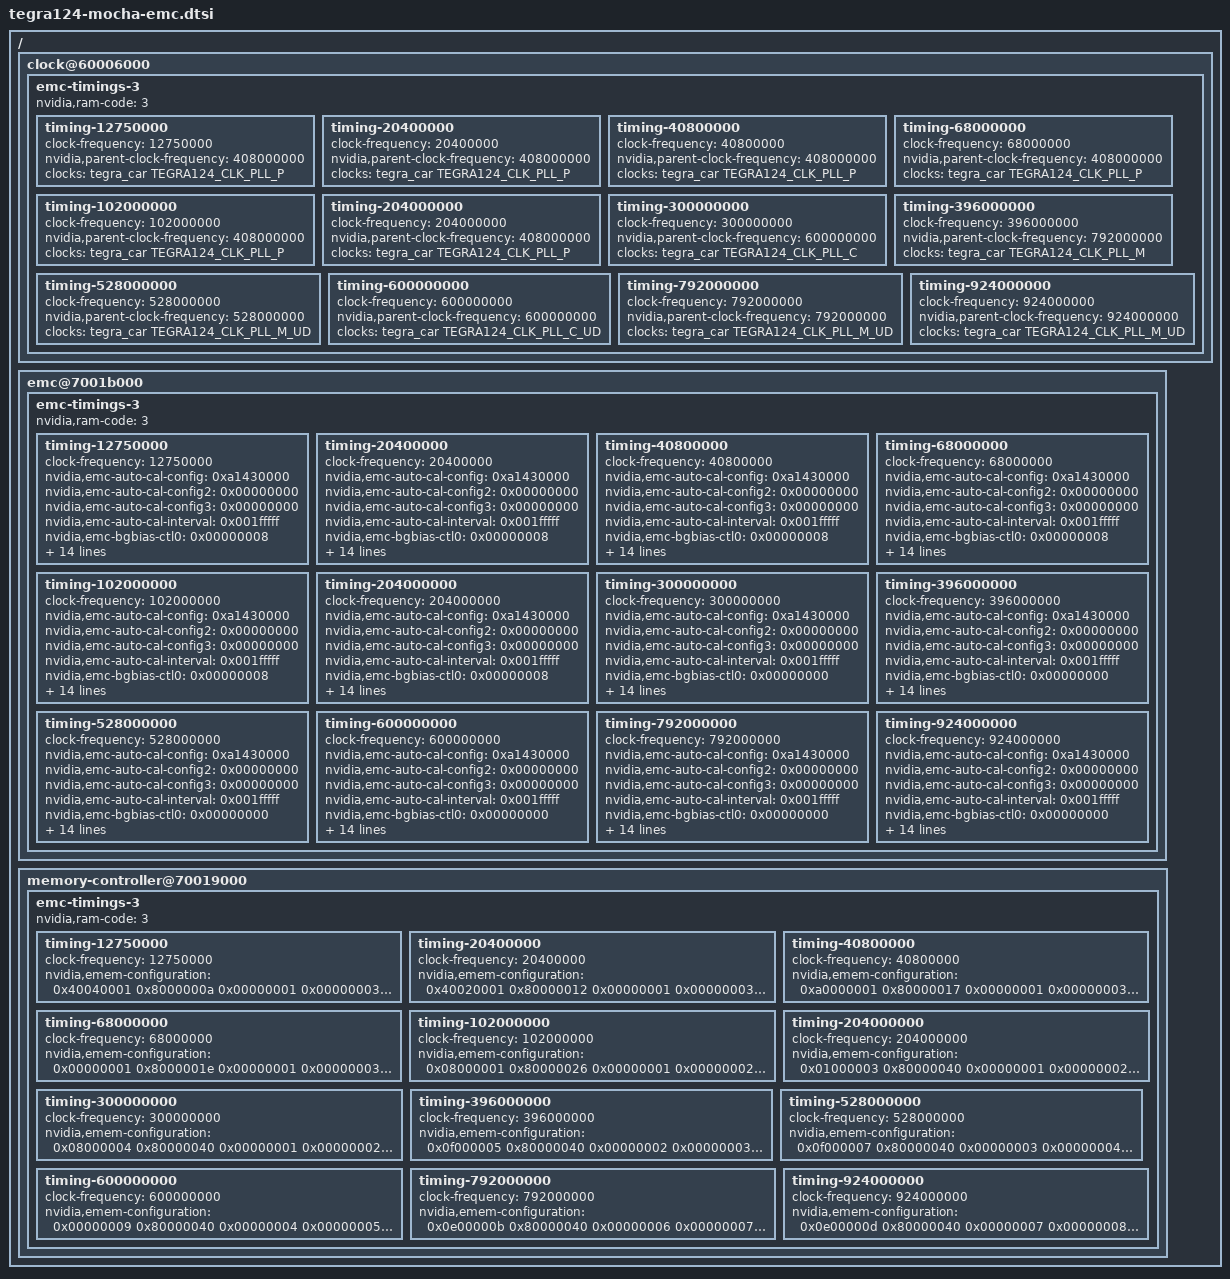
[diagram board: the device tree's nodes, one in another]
/*
 * arch/arm/boot/dts/tegra124-mocha-emc.dtsi
 *
 * Copyright (c) 2018, Dmitry Alexandrov.  All rights reserved.
 *
 * This program is free software; you can redistribute it and/or modify
 * it under the terms of the GNU General Public License as published by
 * the Free Software Foundation; either version 2 of the License, or
 * (at your option) any later version.
 *
 * This program is distributed in the hope that it will be useful, but WITHOUT
 * ANY WARRANTY; without even the implied warranty of MERCHANTABILITY or
 * FITNESS FOR A PARTICULAR PURPOSE.  See the GNU General Public License for
 * more details.
 *
 * You should have received a copy of the GNU General Public License along
 * with this program; if not, write to the Free Software Foundation, Inc.,
 * 51 Franklin Street, Fifth Floor, Boston, MA  02110-1301, USA.
 */
 
/ {
	clock@60006000 {
		emc-timings-3 {
			nvidia,ram-code = <3>;

			timing-12750000 {
				clock-frequency = <12750000>;
				nvidia,parent-clock-frequency = <408000000>;
				clocks = <&tegra_car TEGRA124_CLK_PLL_P>;
				clock-names = "emc-parent";
			};
			timing-20400000 {
				clock-frequency = <20400000>;
				nvidia,parent-clock-frequency = <408000000>;
				clocks = <&tegra_car TEGRA124_CLK_PLL_P>;
				clock-names = "emc-parent";
			};
			timing-40800000 {
				clock-frequency = <40800000>;
				nvidia,parent-clock-frequency = <408000000>;
				clocks = <&tegra_car TEGRA124_CLK_PLL_P>;
				clock-names = "emc-parent";
			};
			timing-68000000 {
				clock-frequency = <68000000>;
				nvidia,parent-clock-frequency = <408000000>;
				clocks = <&tegra_car TEGRA124_CLK_PLL_P>;
				clock-names = "emc-parent";
			};
			timing-102000000 {
				clock-frequency = <102000000>;
				nvidia,parent-clock-frequency = <408000000>;
				clocks = <&tegra_car TEGRA124_CLK_PLL_P>;
				clock-names = "emc-parent";
			};
			timing-204000000 {
				clock-frequency = <204000000>;
				nvidia,parent-clock-frequency = <408000000>;
				clocks = <&tegra_car TEGRA124_CLK_PLL_P>;
				clock-names = "emc-parent";
			};
			timing-300000000 {
				clock-frequency = <300000000>;
				nvidia,parent-clock-frequency = <600000000>;
				clocks = <&tegra_car TEGRA124_CLK_PLL_C>;
				clock-names = "emc-parent";
			};
			timing-396000000 {
				clock-frequency = <396000000>;
				nvidia,parent-clock-frequency = <792000000>;
				clocks = <&tegra_car TEGRA124_CLK_PLL_M>;
				clock-names = "emc-parent";
			};
			timing-528000000 {
				clock-frequency = <528000000>;
				nvidia,parent-clock-frequency = <528000000>;
				clocks = <&tegra_car TEGRA124_CLK_PLL_M_UD>;
				clock-names = "emc-parent";
			};
			timing-600000000 {
				clock-frequency = <600000000>;
				nvidia,parent-clock-frequency = <600000000>;
				clocks = <&tegra_car TEGRA124_CLK_PLL_C_UD>;
				clock-names = "emc-parent";
			};
			timing-792000000 {
				clock-frequency = <792000000>;
				nvidia,parent-clock-frequency = <792000000>;
				clocks = <&tegra_car TEGRA124_CLK_PLL_M_UD>;
				clock-names = "emc-parent";
			};
			timing-924000000 {
				clock-frequency = <924000000>;
				nvidia,parent-clock-frequency = <924000000>;
				clocks = <&tegra_car TEGRA124_CLK_PLL_M_UD>;
				clock-names = "emc-parent";
			};
		};
	};

	emc@7001b000 {
		emc-timings-3 {
			nvidia,ram-code = <3>;

			timing-12750000 {
				clock-frequency = <12750000>;

				nvidia,emc-auto-cal-config = <0xa1430000>;
				nvidia,emc-auto-cal-config2 = <0x00000000>;
				nvidia,emc-auto-cal-config3 = <0x00000000>;
				nvidia,emc-auto-cal-interval = <0x001fffff>;
				nvidia,emc-bgbias-ctl0 = <0x00000008>;
				nvidia,emc-cfg = <0xf3200000>;
				nvidia,emc-cfg-2 = <0x000008c7>;
				nvidia,emc-ctt-term-ctrl = <0x00000802>;
				nvidia,emc-mode-1 = <0x00010083>;
				nvidia,emc-mode-2 = <0x00020004>;
				nvidia,emc-mode-4 = <0x800b0000>;
				nvidia,emc-mode-reset = <0x00000000>;
				nvidia,emc-mrs-wait-cnt = <0x000d0011>;
				nvidia,emc-sel-dpd-ctrl = <0x0004013c>;
				nvidia,emc-xm2dqspadctrl2 = <0x0130b018>;
				nvidia,emc-zcal-cnt-long = <0x00000015>;
				nvidia,emc-zcal-interval = <0x00064000>;

				nvidia,emc-configuration = <
					0x00000000
					0x00000001
					0x00000000
					0x00000002
					0x00000006
					0x00000006
					0x00000008
					0x00000003
					0x0000000a
					0x00000002
					0x00000002
					0x00000001
					0x00000002
					0x00000000
					0x00000003
					0x00000003
					0x00000006
					0x00000002
					0x00000000
					0x00000005
					0x00000005
					0x00010000
					0x00000003
					0x00000000
					0x00000000
					0x00000000
					0x00000000
					0x00000004
					0x0000000c
					0x0000000d
					0x0000000f
					0x00000030
					0x00000000
					0x0000000c
					0x00000002
					0x00000002
					0x00000006
					0x00000000
					0x00000001
					0x0000000c
					0x00000003
					0x00000002
					0x00000003
					0x00000003
					0x00000003
					0x00000006
					0x00000007
					0x00000003
					0x00000003
					0x00000036
					0x00000000
					0x00000000
					0x00000000
					0x1363a296
					0x005800a0
					0x00008000
					0x00090000
					0x00090000
					0x00090000
					0x00090000
					0x00090000
					0x00090000
					0x00090000
					0x00090000
					0x00090000
					0x00090000
					0x00090000
					0x00090000
					0x00090000
					0x00090000
					0x00090000
					0x00090000
					0x00000000
					0x00000000
					0x00000000
					0x00000000
					0x00000000
					0x00000000
					0x00000000
					0x00000000
					0x000fc000
					0x000fc000
					0x00000000
					0x000fc000
					0x000fc000
					0x00000000
					0x00000000
					0x00000000
					0x00000000
					0x00000000
					0x00000000
					0x00000000
					0x00000000
					0x00000000
					0x00000000
					0x00000000
					0x00000000
					0x00000000
					0x00000000
					0x00000000
					0x00000000
					0x00000000
					0x00000000
					0x00000000
					0x00000000
					0x00000000
					0x00000000
					0x00000000
					0x00000000
					0x00000000
					0x000fc000
					0x000fc000
					0x000fc000
					0x000fc000
					0x0000fc00
					0x0000fc00
					0x0000fc00
					0x0000fc00
					0x00000200
					0x00000000
					0x00100100
					0x00000000
					0x00000000
					0x77ffc000
					0x00000303
					0x81f1f008
					0x07070000
					0x0000003f
					0x015ddddd
					0x51451400
					0x00514514
					0x00514514
					0x51451400
					0x0000003f
					0x00000000
					0x00000000
					0x00000011
					0x000d0011
					0x00000000
					0x00000003
					0x0000f3f3
					0x80000164
					0x0000000a
				>;
			};

			timing-20400000 {
				clock-frequency = <20400000>;

				nvidia,emc-auto-cal-config = <0xa1430000>;
				nvidia,emc-auto-cal-config2 = <0x00000000>;
				nvidia,emc-auto-cal-config3 = <0x00000000>;
				nvidia,emc-auto-cal-interval = <0x001fffff>;
				nvidia,emc-bgbias-ctl0 = <0x00000008>;
				nvidia,emc-cfg = <0xf3200000>;
				nvidia,emc-cfg-2 = <0x000008c7>;
				nvidia,emc-ctt-term-ctrl = <0x00000802>;
				nvidia,emc-mode-1 = <0x00010083>;
				nvidia,emc-mode-2 = <0x00020004>;
				nvidia,emc-mode-4 = <0x800b0000>;
				nvidia,emc-mode-reset = <0x00000000>;
				nvidia,emc-mrs-wait-cnt = <0x00150011>;
				nvidia,emc-sel-dpd-ctrl = <0x0004013c>;
				nvidia,emc-xm2dqspadctrl2 = <0x0130b018>;
				nvidia,emc-zcal-cnt-long = <0x00000015>;
				nvidia,emc-zcal-interval = <0x00064000>;

				nvidia,emc-configuration = <
					0x00000001
					0x00000002
					0x00000000
					0x00000002
					0x00000006
					0x00000006
					0x00000008
					0x00000003
					0x0000000a
					0x00000002
					0x00000002
					0x00000001
					0x00000002
					0x00000000
					0x00000003
					0x00000003
					0x00000006
					0x00000002
					0x00000000
					0x00000005
					0x00000005
					0x00010000
					0x00000003
					0x00000000
					0x00000000
					0x00000000
					0x00000000
					0x00000004
					0x0000000c
					0x0000000d
					0x0000000f
					0x0000004d
					0x00000000
					0x00000013
					0x00000002
					0x00000002
					0x00000006
					0x00000000
					0x00000001
					0x0000000c
					0x00000003
					0x00000003
					0x00000003
					0x00000003
					0x00000003
					0x00000006
					0x00000007
					0x00000003
					0x00000003
					0x00000055
					0x00000000
					0x00000000
					0x00000000
					0x1363a296
					0x005800a0
					0x00008000
					0x00090000
					0x00090000
					0x00090000
					0x00090000
					0x00090000
					0x00090000
					0x00090000
					0x00090000
					0x00090000
					0x00090000
					0x00090000
					0x00090000
					0x00090000
					0x00090000
					0x00090000
					0x00090000
					0x00000000
					0x00000000
					0x00000000
					0x00000000
					0x00000000
					0x00000000
					0x00000000
					0x00000000
					0x000fc000
					0x000fc000
					0x00000000
					0x000fc000
					0x000fc000
					0x00000000
					0x00000000
					0x00000000
					0x00000000
					0x00000000
					0x00000000
					0x00000000
					0x00000000
					0x00000000
					0x00000000
					0x00000000
					0x00000000
					0x00000000
					0x00000000
					0x00000000
					0x00000000
					0x00000000
					0x00000000
					0x00000000
					0x00000000
					0x00000000
					0x00000000
					0x00000000
					0x00000000
					0x00000000
					0x000fc000
					0x000fc000
					0x000fc000
					0x000fc000
					0x0000fc00
					0x0000fc00
					0x0000fc00
					0x0000fc00
					0x00000200
					0x00000000
					0x00100100
					0x00000000
					0x00000000
					0x77ffc000
					0x00000303
					0x81f1f008
					0x07070000
					0x0000003f
					0x015ddddd
					0x51451400
					0x00514514
					0x00514514
					0x51451400
					0x0000003f
					0x00000000
					0x00000000
					0x00000011
					0x00150011
					0x00000000
					0x00000003
					0x0000f3f3
					0x8000019f
					0x0000000a
				>;
			};

			timing-40800000 {
				clock-frequency = <40800000>;

				nvidia,emc-auto-cal-config = <0xa1430000>;
				nvidia,emc-auto-cal-config2 = <0x00000000>;
				nvidia,emc-auto-cal-config3 = <0x00000000>;
				nvidia,emc-auto-cal-interval = <0x001fffff>;
				nvidia,emc-bgbias-ctl0 = <0x00000008>;
				nvidia,emc-cfg = <0xf3200000>;
				nvidia,emc-cfg-2 = <0x000008c7>;
				nvidia,emc-ctt-term-ctrl = <0x00000802>;
				nvidia,emc-mode-1 = <0x00010083>;
				nvidia,emc-mode-2 = <0x00020004>;
				nvidia,emc-mode-4 = <0x800b0000>;
				nvidia,emc-mode-reset = <0x00000000>;
				nvidia,emc-mrs-wait-cnt = <0x00290011>;
				nvidia,emc-sel-dpd-ctrl = <0x0004013c>;
				nvidia,emc-xm2dqspadctrl2 = <0x0130b018>;
				nvidia,emc-zcal-cnt-long = <0x00000015>;
				nvidia,emc-zcal-interval = <0x00064000>;

				nvidia,emc-configuration = <
					0x00000002
					0x00000005
					0x00000000
					0x00000002
					0x00000006
					0x00000006
					0x00000008
					0x00000003
					0x0000000a
					0x00000002
					0x00000002
					0x00000001
					0x00000002
					0x00000000
					0x00000003
					0x00000003
					0x00000006
					0x00000002
					0x00000000
					0x00000005
					0x00000005
					0x00010000
					0x00000003
					0x00000000
					0x00000000
					0x00000000
					0x00000000
					0x00000004
					0x0000000c
					0x0000000d
					0x0000000f
					0x0000009a
					0x00000000
					0x00000026
					0x00000002
					0x00000002
					0x00000006
					0x00000000
					0x00000001
					0x0000000c
					0x00000006
					0x00000006
					0x00000003
					0x00000003
					0x00000003
					0x00000006
					0x00000008
					0x00000003
					0x00000003
					0x000000aa
					0x00000000
					0x00000000
					0x00000000
					0x1363a296
					0x005800a0
					0x00008000
					0x00090000
					0x00090000
					0x00090000
					0x00090000
					0x00090000
					0x00090000
					0x00090000
					0x00090000
					0x00090000
					0x00090000
					0x00090000
					0x00090000
					0x00090000
					0x00090000
					0x00090000
					0x00090000
					0x00000000
					0x00000000
					0x00000000
					0x00000000
					0x00000000
					0x00000000
					0x00000000
					0x00000000
					0x000fc000
					0x000fc000
					0x00000000
					0x000fc000
					0x000fc000
					0x00000000
					0x00000000
					0x00000000
					0x00000000
					0x00000000
					0x00000000
					0x00000000
					0x00000000
					0x00000000
					0x00000000
					0x00000000
					0x00000000
					0x00000000
					0x00000000
					0x00000000
					0x00000000
					0x00000000
					0x00000000
					0x00000000
					0x00000000
					0x00000000
					0x00000000
					0x00000000
					0x00000000
					0x00000000
					0x000fc000
					0x000fc000
					0x000fc000
					0x000fc000
					0x0000fc00
					0x0000fc00
					0x0000fc00
					0x0000fc00
					0x00000200
					0x00000000
					0x00100100
					0x00000000
					0x00000000
					0x77ffc000
					0x00000303
					0x81f1f008
					0x07070000
					0x0000003f
					0x015ddddd
					0x51451400
					0x00514514
					0x00514514
					0x51451400
					0x0000003f
					0x00000000
					0x00000000
					0x00000011
					0x00290011
					0x00000000
					0x00000003
					0x0000f3f3
					0x8000023a
					0x0000000a
				>;
			};

			timing-68000000 {
				clock-frequency = <68000000>;

				nvidia,emc-auto-cal-config = <0xa1430000>;
				nvidia,emc-auto-cal-config2 = <0x00000000>;
				nvidia,emc-auto-cal-config3 = <0x00000000>;
				nvidia,emc-auto-cal-interval = <0x001fffff>;
				nvidia,emc-bgbias-ctl0 = <0x00000008>;
				nvidia,emc-cfg = <0xf3200000>;
				nvidia,emc-cfg-2 = <0x000008c7>;
				nvidia,emc-ctt-term-ctrl = <0x00000802>;
				nvidia,emc-mode-1 = <0x00010083>;
				nvidia,emc-mode-2 = <0x00020004>;
				nvidia,emc-mode-4 = <0x800b0000>;
				nvidia,emc-mode-reset = <0x00000000>;
				nvidia,emc-mrs-wait-cnt = <0x00440011>;
				nvidia,emc-sel-dpd-ctrl = <0x0004013c>;
				nvidia,emc-xm2dqspadctrl2 = <0x0130b018>;
				nvidia,emc-zcal-cnt-long = <0x00000015>;
				nvidia,emc-zcal-interval = <0x00064000>;

				nvidia,emc-configuration = <
					0x00000004
					0x00000008
					0x00000000
					0x00000002
					0x00000006
					0x00000006
					0x00000008
					0x00000003
					0x0000000a
					0x00000002
					0x00000002
					0x00000001
					0x00000002
					0x00000000
					0x00000003
					0x00000003
					0x00000006
					0x00000002
					0x00000000
					0x00000005
					0x00000005
					0x00010000
					0x00000003
					0x00000000
					0x00000000
					0x00000000
					0x00000000
					0x00000004
					0x0000000c
					0x0000000d
					0x0000000f
					0x00000101
					0x00000000
					0x00000040
					0x00000002
					0x00000002
					0x00000006
					0x00000000
					0x00000001
					0x0000000c
					0x0000000a
					0x0000000a
					0x00000003
					0x00000003
					0x00000003
					0x00000006
					0x00000008
					0x00000003
					0x00000003
					0x0000011b
					0x00000000
					0x00000000
					0x00000000
					0x1363a296
					0x005800a0
					0x00008000
					0x00090000
					0x00090000
					0x00090000
					0x00090000
					0x00090000
					0x00090000
					0x00090000
					0x00090000
					0x00090000
					0x00090000
					0x00090000
					0x00090000
					0x00090000
					0x00090000
					0x00090000
					0x00090000
					0x00000000
					0x00000000
					0x00000000
					0x00000000
					0x00000000
					0x00000000
					0x00000000
					0x00000000
					0x000fc000
					0x000fc000
					0x00000000
					0x000fc000
					0x000fc000
					0x00000000
					0x00000000
					0x00000000
					0x00000000
					0x00000000
					0x00000000
					0x00000000
					0x00000000
					0x00000000
					0x00000000
					0x00000000
					0x00000000
					0x00000000
					0x00000000
					0x00000000
					0x00000000
					0x00000000
					0x00000000
					0x00000000
					0x00000000
					0x00000000
					0x00000000
					0x00000000
					0x00000000
					0x00000000
					0x000fc000
					0x000fc000
					0x000fc000
					0x000fc000
					0x0000fc00
					0x0000fc00
					0x0000fc00
					0x0000fc00
					0x00000200
					0x00000000
					0x00100100
					0x00000000
					0x00000000
					0x77ffc000
					0x00000303
					0x81f1f008
					0x07070000
					0x0000003f
					0x015ddddd
					0x51451400
					0x00514514
					0x00514514
					0x51451400
					0x0000003f
					0x00000000
					0x00000000
					0x00000019
					0x00440011
					0x00000000
					0x00000003
					0x0000f3f3
					0x80000309
					0x0000000a
				>;
			};

			timing-102000000 {
				clock-frequency = <102000000>;

				nvidia,emc-auto-cal-config = <0xa1430000>;
				nvidia,emc-auto-cal-config2 = <0x00000000>;
				nvidia,emc-auto-cal-config3 = <0x00000000>;
				nvidia,emc-auto-cal-interval = <0x001fffff>;
				nvidia,emc-bgbias-ctl0 = <0x00000008>;
				nvidia,emc-cfg = <0xf3200000>;
				nvidia,emc-cfg-2 = <0x000008c7>;
				nvidia,emc-ctt-term-ctrl = <0x00000802>;
				nvidia,emc-mode-1 = <0x00010083>;
				nvidia,emc-mode-2 = <0x00020004>;
				nvidia,emc-mode-4 = <0x800b0000>;
				nvidia,emc-mode-reset = <0x00000000>;
				nvidia,emc-mrs-wait-cnt = <0x00660011>;
				nvidia,emc-sel-dpd-ctrl = <0x0004013c>;
				nvidia,emc-xm2dqspadctrl2 = <0x0130b018>;
				nvidia,emc-zcal-cnt-long = <0x00000015>;
				nvidia,emc-zcal-interval = <0x00064000>;

				nvidia,emc-configuration = <
					0x00000006
					0x0000000d
					0x00000000
					0x00000004
					0x00000005
					0x00000006
					0x00000008
					0x00000003
					0x0000000a
					0x00000002
					0x00000002
					0x00000001
					0x00000002
					0x00000000
					0x00000003
					0x00000003
					0x00000006
					0x00000002
					0x00000000
					0x00000005
					0x00000005
					0x00010000
					0x00000003
					0x00000000
					0x00000000
					0x00000000
					0x00000000
					0x00000004
					0x0000000c
					0x0000000d
					0x0000000f
					0x00000182
					0x00000000
					0x00000060
					0x00000002
					0x00000002
					0x00000005
					0x00000000
					0x00000001
					0x0000000c
					0x0000000f
					0x0000000f
					0x00000003
					0x00000003
					0x00000003
					0x00000006
					0x00000007
					0x00000003
					0x00000003
					0x000001a9
					0x00000000
					0x00000000
					0x00000000
					0x1363a296
					0x005800a0
					0x00008000
					0x00090000
					0x00090000
					0x00090000
					0x00090000
					0x00090000
					0x00090000
					0x00090000
					0x00090000
					0x00090000
					0x00090000
					0x00090000
					0x00090000
					0x00090000
					0x00090000
					0x00090000
					0x00090000
					0x00000000
					0x00000000
					0x00000000
					0x00000000
					0x00000000
					0x00000000
					0x00000000
					0x00000000
					0x000fc000
					0x000fc000
					0x00000000
					0x000fc000
					0x000fc000
					0x00000000
					0x00000000
					0x00000000
					0x00000000
					0x00000000
					0x00000000
					0x00000000
					0x00000000
					0x00000000
					0x00000000
					0x00000000
					0x00000000
					0x00000000
					0x00000000
					0x00000000
					0x00000000
					0x00000000
					0x00000000
					0x00000000
					0x00000000
					0x00000000
					0x00000000
					0x00000000
					0x00000000
					0x00000000
					0x000fc000
					0x000fc000
					0x000fc000
					0x000fc000
					0x0000fc00
					0x0000fc00
					0x0000fc00
					0x0000fc00
					0x00000200
					0x00000000
					0x00100100
					0x00000000
					0x00000000
					0x77ffc000
					0x00000303
					0x81f1f008
					0x07070000
					0x0000003f
					0x015ddddd
					0x51451400
					0x00514514
					0x00514514
					0x51451400
					0x0000003f
					0x00000000
					0x00000000
					0x00000025
					0x00660011
					0x00000000
					0x00000003
					0x0000f3f3
					0x8000040b
					0x0000000a
				>;
			};

			timing-204000000 {
				clock-frequency = <204000000>;

				nvidia,emc-auto-cal-config = <0xa1430000>;
				nvidia,emc-auto-cal-config2 = <0x00000000>;
				nvidia,emc-auto-cal-config3 = <0x00000000>;
				nvidia,emc-auto-cal-interval = <0x001fffff>;
				nvidia,emc-bgbias-ctl0 = <0x00000008>;
				nvidia,emc-cfg = <0xf3200000>;
				nvidia,emc-cfg-2 = <0x000008cf>;
				nvidia,emc-ctt-term-ctrl = <0x00000802>;
				nvidia,emc-mode-1 = <0x00010083>;
				nvidia,emc-mode-2 = <0x00020004>;
				nvidia,emc-mode-4 = <0x800b0000>;
				nvidia,emc-mode-reset = <0x00000000>;
				nvidia,emc-mrs-wait-cnt = <0x00cc0011>;
				nvidia,emc-sel-dpd-ctrl = <0x0004013c>;
				nvidia,emc-xm2dqspadctrl2 = <0x0130b018>;
				nvidia,emc-zcal-cnt-long = <0x00000017>;
				nvidia,emc-zcal-interval = <0x00064000>;

				nvidia,emc-configuration = <
					0x0000000c
					0x0000001a
					0x00000000
					0x00000008
					0x00000005
					0x00000007
					0x00000008
					0x00000003
					0x0000000a
					0x00000003
					0x00000003
					0x00000002
					0x00000003
					0x00000000
					0x00000002
					0x00000002
					0x00000005
					0x00000003
					0x00000000
					0x00000003
					0x00000007
					0x00010000
					0x00000004
					0x00000000
					0x00000000
					0x00000000
					0x00000000
					0x00000002
					0x0000000e
					0x0000000f
					0x00000011
					0x00000304
					0x00000000
					0x000000c1
					0x00000002
					0x00000002
					0x00000005
					0x00000000
					0x00000001
					0x0000000c
					0x0000001d
					0x0000001d
					0x00000003
					0x00000004
					0x00000003
					0x00000009
					0x00000007
					0x00000003
					0x00000003
					0x00000351
					0x00000000
					0x00000000
					0x00000000
					0x1363a296
					0x005800a0
					0x00008000
					0x00070000
					0x00070000
					0x00070000
					0x00070000
					0x00070000
					0x00070000
					0x00070000
					0x00070000
					0x00070000
					0x00070000
					0x00070000
					0x00070000
					0x00070000
					0x00070000
					0x00070000
					0x00070000
					0x00000000
					0x00000000
					0x00000000
					0x00000000
					0x00000000
					0x00000000
					0x00000000
					0x00000000
					0x00098000
					0x00098000
					0x00000000
					0x00098000
					0x00098000
					0x00000000
					0x00000000
					0x00000000
					0x00000000
					0x00000000
					0x00000000
					0x00000000
					0x00000000
					0x00000000
					0x00000000
					0x00000000
					0x00000000
					0x00000000
					0x00000000
					0x00000000
					0x00000000
					0x00000000
					0x00000000
					0x00000000
					0x00000000
					0x00000000
					0x00000000
					0x00000000
					0x00000000
					0x00000000
					0x00080000
					0x00080000
					0x00080000
					0x00080000
					0x00008000
					0x00008000
					0x00008000
					0x00008000
					0x00000200
					0x00000000
					0x00100100
					0x00000000
					0x00000000
					0x77ffc000
					0x00000303
					0x81f1f008
					0x07070000
					0x0000003f
					0x015ddddd
					0x51451400
					0x00514514
					0x00514514
					0x51451400
					0x0000003f
					0x00000000
					0x00000000
					0x0000004a
					0x00cc0011
					0x00000000
					0x00000004
					0x0000d3b3
					0x80000713
					0x0000000a
				>;
			};

			timing-300000000 {
				clock-frequency = <300000000>;

				nvidia,emc-auto-cal-config = <0xa1430000>;
				nvidia,emc-auto-cal-config2 = <0x00000000>;
				nvidia,emc-auto-cal-config3 = <0x00000000>;
				nvidia,emc-auto-cal-interval = <0x001fffff>;
				nvidia,emc-bgbias-ctl0 = <0x00000000>;
				nvidia,emc-cfg = <0xf3300000>;
				nvidia,emc-cfg-2 = <0x000008d7>;
				nvidia,emc-ctt-term-ctrl = <0x00000802>;
				nvidia,emc-mode-1 = <0x00010083>;
				nvidia,emc-mode-2 = <0x00020004>;
				nvidia,emc-mode-4 = <0x800b0000>;
				nvidia,emc-mode-reset = <0x00000000>;
				nvidia,emc-mrs-wait-cnt = <0x012c0011>;
				nvidia,emc-sel-dpd-ctrl = <0x0004013c>;
				nvidia,emc-xm2dqspadctrl2 = <0x01231239>;
				nvidia,emc-zcal-cnt-long = <0x0000001f>;
				nvidia,emc-zcal-interval = <0x00064000>;

				nvidia,emc-configuration = <
					0x00000011
					0x00000026
					0x00000000
					0x0000000c
					0x00000005
					0x00000007
					0x00000008
					0x00000003
					0x0000000a
					0x00000005
					0x00000005
					0x00000002
					0x00000003
					0x00000000
					0x00000002
					0x00000002
					0x00000006
					0x00000003
					0x00000000
					0x00000003
					0x00000008
					0x00030000
					0x00000004
					0x00000000
					0x00000000
					0x00000000
					0x00000000
					0x00000002
					0x0000000f
					0x00000012
					0x00000014
					0x0000046e
					0x00000000
					0x0000011b
					0x00000002
					0x00000002
					0x00000005
					0x00000000
					0x00000001
					0x0000000c
					0x0000002a
					0x0000002a
					0x00000003
					0x00000005
					0x00000003
					0x0000000d
					0x00000007
					0x00000003
					0x00000003
					0x000004e0
					0x00000000
					0x00000000
					0x00000000
					0x1363a096
					0x005800a0
					0x00008000
					0x00020000
					0x00020000
					0x00020000
					0x00020000
					0x00020000
					0x00020000
					0x00020000
					0x00020000
					0x00020000
					0x00020000
					0x00020000
					0x00020000
					0x00020000
					0x00020000
					0x00020000
					0x00020000
					0x00000000
					0x00000000
					0x00000000
					0x00000000
					0x00000000
					0x00000000
					0x00000000
					0x00000000
					0x00058000
					0x00058000
					0x00000000
					0x00058000
					0x00058000
					0x00000000
					0x00000000
					0x00000000
					0x00000000
					0x00000000
					0x00000000
					0x00000000
					0x00000000
					0x00000000
					0x00000000
					0x00000000
					0x00000000
					0x00000000
					0x00000000
					0x00000000
					0x00000000
					0x00000000
					0x00000000
					0x00000000
					0x00000000
					0x00000000
					0x00000000
					0x00000000
					0x00000000
					0x00000000
					0x00058000
					0x00058000
					0x00058000
					0x00058000
					0x00005c00
					0x00005800
					0x00005c00
					0x00005800
					0x00000200
					0x00000000
					0x00100100
					0x00000000
					0x00000000
					0x77ffc000
					0x00000303
					0x81f1f008
					0x07070000
					0x0000003f
					0x015ddddd
					0x51451420
					0x00514514
					0x00514514
					0x51451400
					0x0000003f
					0x00000000
					0x00000000
					0x0000006c
					0x012c0011
					0x00000000
					0x00000004
					0x000052a3
					0x800009ed
					0x0000000b
				>;
			};

			timing-396000000 {
				clock-frequency = <396000000>;

				nvidia,emc-auto-cal-config = <0xa1430000>;
				nvidia,emc-auto-cal-config2 = <0x00000000>;
				nvidia,emc-auto-cal-config3 = <0x00000000>;
				nvidia,emc-auto-cal-interval = <0x001fffff>;
				nvidia,emc-bgbias-ctl0 = <0x00000000>;
				nvidia,emc-cfg = <0xf3300000>;
				nvidia,emc-cfg-2 = <0x00000897>;
				nvidia,emc-ctt-term-ctrl = <0x00000802>;
				nvidia,emc-mode-1 = <0x00010083>;
				nvidia,emc-mode-2 = <0x00020004>;
				nvidia,emc-mode-4 = <0x800b0000>;
				nvidia,emc-mode-reset = <0x00000000>;
				nvidia,emc-mrs-wait-cnt = <0x018c0011>;
				nvidia,emc-sel-dpd-ctrl = <0x0004001c>;
				nvidia,emc-xm2dqspadctrl2 = <0x01231239>;
				nvidia,emc-zcal-cnt-long = <0x00000028>;
				nvidia,emc-zcal-interval = <0x00064000>;

				nvidia,emc-configuration = <
					0x00000017
					0x00000033
					0x00000000
					0x00000010
					0x00000007
					0x00000008
					0x00000008
					0x00000003
					0x0000000a
					0x00000007
					0x00000007
					0x00000003
					0x00000003
					0x00000000
					0x00000002
					0x00000002
					0x00000006
					0x00000003
					0x00000000
					0x00000002
					0x00000009
					0x00030000
					0x00000004
					0x00000000
					0x00000000
					0x00000000
					0x00000000
					0x00000001
					0x00000010
					0x00000012
					0x00000014
					0x000005d9
					0x00000000
					0x00000176
					0x00000002
					0x00000002
					0x00000007
					0x00000000
					0x00000001
					0x0000000e
					0x00000038
					0x00000038
					0x00000003
					0x00000006
					0x00000003
					0x00000012
					0x00000009
					0x00000003
					0x00000003
					0x00000670
					0x00000000
					0x00000000
					0x00000000
					0x1363a096
					0x005800a0
					0x00008000
					0x00020000
					0x00020000
					0x00020000
					0x00020000
					0x00020000
					0x00020000
					0x00020000
					0x00020000
					0x00020000
					0x00020000
					0x00020000
					0x00020000
					0x00020000
					0x00020000
					0x00020000
					0x00020000
					0x00000000
					0x00000000
					0x00000000
					0x00000000
					0x00000000
					0x00000000
					0x00000000
					0x00000000
					0x00048000
					0x00048000
					0x00000000
					0x00048000
					0x00048000
					0x00000000
					0x00000000
					0x00000000
					0x00000000
					0x00000000
					0x00000000
					0x00000000
					0x00000000
					0x00000000
					0x00000000
					0x00000000
					0x00000000
					0x00000000
					0x00000000
					0x00000000
					0x00000000
					0x00000000
					0x00000000
					0x00000000
					0x00000000
					0x00000000
					0x00000000
					0x00000000
					0x00000000
					0x00000000
					0x00040000
					0x00040000
					0x00040000
					0x00040000
					0x00004000
					0x00004000
					0x00004000
					0x00004000
					0x00000200
					0x00000000
					0x00100100
					0x00000000
					0x00000000
					0x77ffc000
					0x00000303
					0x81f1f008
					0x07070000
					0x0000003f
					0x015ddddd
					0x51451420
					0x00514514
					0x00514514
					0x51451400
					0x0000003f
					0x00000000
					0x00000000
					0x0000008f
					0x018c0011
					0x00000000
					0x00000004
					0x000052a3
					0x80000cc7
					0x0000000b
				>;
			};

			timing-528000000 {
				clock-frequency = <528000000>;

				nvidia,emc-auto-cal-config = <0xa1430000>;
				nvidia,emc-auto-cal-config2 = <0x00000000>;
				nvidia,emc-auto-cal-config3 = <0x00000000>;
				nvidia,emc-auto-cal-interval = <0x001fffff>;
				nvidia,emc-bgbias-ctl0 = <0x00000000>;
				nvidia,emc-cfg = <0xf3300000>;
				nvidia,emc-cfg-2 = <0x0000089f>;
				nvidia,emc-ctt-term-ctrl = <0x00000802>;
				nvidia,emc-mode-1 = <0x000100c3>;
				nvidia,emc-mode-2 = <0x00020006>;
				nvidia,emc-mode-4 = <0x800b0000>;
				nvidia,emc-mode-reset = <0x00000000>;
				nvidia,emc-mrs-wait-cnt = <0x02100013>;
				nvidia,emc-sel-dpd-ctrl = <0x0004001c>;
				nvidia,emc-xm2dqspadctrl2 = <0x0123123d>;
				nvidia,emc-zcal-cnt-long = <0x00000034>;
				nvidia,emc-zcal-interval = <0x00064000>;

				nvidia,emc-configuration = <
					0x0000001f
					0x00000044
					0x00000000
					0x00000016
					0x00000009
					0x00000009
					0x00000009
					0x00000003
					0x0000000d
					0x00000009
					0x00000009
					0x00000005
					0x00000004
					0x00000000
					0x00000002
					0x00000002
					0x00000008
					0x00000003
					0x00000000
					0x00000003
					0x0000000a
					0x00050000
					0x00000004
					0x00000000
					0x00000000
					0x00000000
					0x00000000
					0x00000002
					0x00000011
					0x00000015
					0x00000017
					0x000007cd
					0x00000000
					0x000001f3
					0x00000003
					0x00000003
					0x00000009
					0x00000000
					0x00000001
					0x00000011
					0x0000004a
					0x0000004a
					0x00000004
					0x00000008
					0x00000004
					0x00000019
					0x0000000c
					0x00000003
					0x00000003
					0x00000895
					0x00000000
					0x00000000
					0x00000000
					0x1363a096
					0xe01200b9
					0x00008000
					0x0000000a
					0x0000000a
					0x0000000a
					0x0000000a
					0x0000000a
					0x0000000a
					0x0000000a
					0x0000000a
					0x0000000a
					0x0000000a
					0x0000000a
					0x0000000a
					0x0000000a
					0x0000000a
					0x0000000a
					0x0000000a
					0x00000000
					0x00000000
					0x00000000
					0x00000000
					0x00000000
					0x00000000
					0x00000000
					0x00000000
					0x0000400e
					0x0000400e
					0x00000000
					0x00004010
					0x00004010
					0x00000000
					0x00000000
					0x00000000
					0x00000000
					0x00000000
					0x00000000
					0x00000000
					0x00000000
					0x00000000
					0x00000001
					0x00000001
					0x00000000
					0x00000000
					0x00000000
					0x00000000
					0x00000001
					0x00000000
					0x00000001
					0x00000001
					0x00000000
					0x00000000
					0x00000000
					0x00000000
					0x00000001
					0x00000000
					0x0000000c
					0x0000000c
					0x0000000c
					0x0000000c
					0x0000000d
					0x0000000c
					0x0000000d
					0x0000000c
					0x00000220
					0x00000000
					0x00100100
					0x00000000
					0x00000000
					0x77ffc004
					0x00000303
					0x81f1f008
					0x07070000
					0x0000003f
					0x015ddddd
					0x51451420
					0x00514514
					0x00514514
					0x51451400
					0x0000003f
					0x00000000
					0x00000000
					0x000000bf
					0x02100013
					0x00000000
					0x00000004
					0x000042a0
					0x800010b3
					0x0000000d
				>;
			};

			timing-600000000 {
				clock-frequency = <600000000>;

				nvidia,emc-auto-cal-config = <0xa1430000>;
				nvidia,emc-auto-cal-config2 = <0x00000000>;
				nvidia,emc-auto-cal-config3 = <0x00000000>;
				nvidia,emc-auto-cal-interval = <0x001fffff>;
				nvidia,emc-bgbias-ctl0 = <0x00000000>;
				nvidia,emc-cfg = <0xf3300000>;
				nvidia,emc-cfg-2 = <0x0000089f>;
				nvidia,emc-ctt-term-ctrl = <0x00000802>;
				nvidia,emc-mode-1 = <0x000100e3>;
				nvidia,emc-mode-2 = <0x00020007>;
				nvidia,emc-mode-4 = <0x800b0000>;
				nvidia,emc-mode-reset = <0x00000000>;
				nvidia,emc-mrs-wait-cnt = <0x02580014>;
				nvidia,emc-sel-dpd-ctrl = <0x0004001c>;
				nvidia,emc-xm2dqspadctrl2 = <0x0121103d>;
				nvidia,emc-zcal-cnt-long = <0x0000003a>;
				nvidia,emc-zcal-interval = <0x00064000>;

				nvidia,emc-configuration = <
					0x00000023
					0x0000004d
					0x00000000
					0x00000019
					0x0000000a
					0x0000000a
					0x0000000b
					0x00000004
					0x0000000f
					0x0000000a
					0x0000000a
					0x00000005
					0x00000004
					0x00000000
					0x00000004
					0x00000004
					0x0000000a
					0x00000004
					0x00000000
					0x00000003
					0x0000000d
					0x00070000
					0x00000005
					0x00000000
					0x00000000
					0x00000000
					0x00000000
					0x00000002
					0x00000014
					0x00000018
					0x0000001a
					0x000008e4
					0x00000000
					0x00000239
					0x00000004
					0x00000004
					0x0000000a
					0x00000000
					0x00000001
					0x00000013
					0x00000054
					0x00000054
					0x00000005
					0x00000009
					0x00000005
					0x0000001c
					0x0000000d
					0x00000003
					0x00000003
					0x000009c0
					0x00000000
					0x00000000
					0x00000000
					0x1363a096
					0xe00e00b9
					0x00008000
					0x0000000a
					0x0000000a
					0x0000000a
					0x0000000a
					0x0000000a
					0x0000000a
					0x0000000a
					0x0000000a
					0x0000000a
					0x0000000a
					0x0000000a
					0x0000000a
					0x0000000a
					0x0000000a
					0x0000000a
					0x0000000a
					0x00000000
					0x00000000
					0x00000000
					0x00000000
					0x00000000
					0x00000000
					0x00000000
					0x00000000
					0x0000000e
					0x0000000e
					0x00000000
					0x00000010
					0x00000010
					0x00000000
					0x00000000
					0x00000000
					0x00000000
					0x00000000
					0x00000000
					0x00000000
					0x00000000
					0x00000000
					0x00000003
					0x00000003
					0x00000002
					0x00000002
					0x00000002
					0x00000001
					0x00000003
					0x00000001
					0x00000003
					0x00000003
					0x00000002
					0x00000002
					0x00000002
					0x00000001
					0x00000003
					0x00000001
					0x0000000b
					0x0000000b
					0x0000000b
					0x0000000b
					0x0000000c
					0x0000000b
					0x0000000c
					0x0000000b
					0x00000220
					0x00000000
					0x00100100
					0x00000000
					0x00000000
					0x77ffc004
					0x00000303
					0x81f1f008
					0x07070000
					0x0000003f
					0x015ddddd
					0x51451420
					0x00514514
					0x00514514
					0x51451400
					0x0000003f
					0x00000000
					0x00000000
					0x000000d8
					0x02580014
					0x00000000
					0x00000005
					0x000040a0
					0x800012d6
					0x00000010
				>;
			};

			timing-792000000 {
				clock-frequency = <792000000>;

				nvidia,emc-auto-cal-config = <0xa1430000>;
				nvidia,emc-auto-cal-config2 = <0x00000000>;
				nvidia,emc-auto-cal-config3 = <0x00000000>;
				nvidia,emc-auto-cal-interval = <0x001fffff>;
				nvidia,emc-bgbias-ctl0 = <0x00000000>;
				nvidia,emc-cfg = <0xf3300000>;
				nvidia,emc-cfg-2 = <0x0000089f>;
				nvidia,emc-ctt-term-ctrl = <0x00000802>;
				nvidia,emc-mode-1 = <0x00010043>;
				nvidia,emc-mode-2 = <0x0002001a>;
				nvidia,emc-mode-4 = <0x800b0000>;
				nvidia,emc-mode-reset = <0x00000000>;
				nvidia,emc-mrs-wait-cnt = <0x03180017>;
				nvidia,emc-sel-dpd-ctrl = <0x0004001c>;
				nvidia,emc-xm2dqspadctrl2 = <0x0120103d>;
				nvidia,emc-zcal-cnt-long = <0x0000004c>;
				nvidia,emc-zcal-interval = <0x00064000>;

				nvidia,emc-configuration = <
					0x0000002f
					0x00000066
					0x00000000
					0x00000021
					0x0000000e
					0x0000000d
					0x0000000d
					0x00000005
					0x00000013
					0x0000000e
					0x0000000e
					0x00000007
					0x00000004
					0x00000000
					0x00000005
					0x00000005
					0x0000000e
					0x00000004
					0x00000000
					0x00000005
					0x0000000f
					0x000b0000
					0x00000006
					0x00000000
					0x00000000
					0x00000000
					0x00000000
					0x00000004
					0x00000016
					0x0000001d
					0x0000001f
					0x00000bd1
					0x00000000
					0x000002f4
					0x00000005
					0x00000005
					0x0000000e
					0x00000000
					0x00000001
					0x00000017
					0x0000006f
					0x0000006f
					0x00000006
					0x0000000c
					0x00000006
					0x00000026
					0x00000011
					0x00000003
					0x00000003
					0x00000cdf
					0x00000000
					0x00000000
					0x00000000
					0x1363a096
					0xe00700b9
					0x00008000
					0x00000008
					0x00000008
					0x00000008
					0x00000008
					0x00000008
					0x00000008
					0x00000008
					0x00000008
					0x00000008
					0x00000008
					0x00000008
					0x00000008
					0x00000008
					0x00000008
					0x00000008
					0x00000008
					0x00000000
					0x00000000
					0x00000000
					0x00000000
					0x00000000
					0x00000000
					0x00000000
					0x00000000
					0x0000400d
					0x0000400d
					0x00000000
					0x00004010
					0x00004010
					0x00000000
					0x00000000
					0x00000000
					0x00000000
					0x00000000
					0x00000000
					0x00000000
					0x00000000
					0x00000000
					0x00000007
					0x00000007
					0x00000006
					0x00000006
					0x00000006
					0x00000005
					0x00000006
					0x00000005
					0x00000007
					0x00000007
					0x00000006
					0x00000006
					0x00000006
					0x00000005
					0x00000006
					0x00000005
					0x0000000a
					0x0000000a
					0x0000000a
					0x0000000a
					0x0000000b
					0x0000000a
					0x0000000b
					0x0000000a
					0x00000220
					0x00000000
					0x00100100
					0x00000000
					0x00000000
					0x77ffc004
					0x00000303
					0x81f1f008
					0x07070000
					0x00000000
					0x015ddddd
					0x61861820
					0x00514514
					0x00514514
					0x61861800
					0x0000003f
					0x00000000
					0x00000000
					0x0000011e
					0x03180017
					0x00000000
					0x00000006
					0x00004080
					0x8000188b
					0x00000014
				>;
			};

			timing-924000000 {
				clock-frequency = <924000000>;

				nvidia,emc-auto-cal-config = <0xa1430000>;
				nvidia,emc-auto-cal-config2 = <0x00000000>;
				nvidia,emc-auto-cal-config3 = <0x00000000>;
				nvidia,emc-auto-cal-interval = <0x001fffff>;
				nvidia,emc-bgbias-ctl0 = <0x00000000>;
				nvidia,emc-cfg = <0xf3300000>;
				nvidia,emc-cfg-2 = <0x0000089f>;
				nvidia,emc-ctt-term-ctrl = <0x00000802>;
				nvidia,emc-mode-1 = <0x00010083>;
				nvidia,emc-mode-2 = <0x0002001c>;
				nvidia,emc-mode-4 = <0x800b0000>;
				nvidia,emc-mode-reset = <0x00000000>;
				nvidia,emc-mrs-wait-cnt = <0x039c0019>;
				nvidia,emc-sel-dpd-ctrl = <0x0004001c>;
				nvidia,emc-xm2dqspadctrl2 = <0x0120103d>;
				nvidia,emc-zcal-cnt-long = <0x00000058>;
				nvidia,emc-zcal-interval = <0x00064000>;

				nvidia,emc-configuration = <
					0x00000037
					0x00000078
					0x00000000
					0x00000026
					0x00000010
					0x0000000f
					0x00000010
					0x00000006
					0x00000017
					0x00000010
					0x00000010
					0x00000009
					0x00000005
					0x00000000
					0x00000007
					0x00000007
					0x00000010
					0x00000005
					0x00000000
					0x00000005
					0x00000012
					0x000d0000
					0x00000007
					0x00000000
					0x00000000
					0x00000000
					0x00000000
					0x00000004
					0x00000019
					0x00000020
					0x00000022
					0x00000dd4
					0x00000000
					0x00000375
					0x00000006
					0x00000006
					0x00000010
					0x00000000
					0x00000001
					0x0000001b
					0x00000082
					0x00000082
					0x00000007
					0x0000000e
					0x00000007
					0x0000002d
					0x00000014
					0x00000003
					0x00000003
					0x00000f04
					0x00000000
					0x00000000
					0x00000000
					0x1363a896
					0xe00400b9
					0x00008000
					0x00000004
					0x00000004
					0x00000004
					0x00000004
					0x00000004
					0x00000004
					0x00000004
					0x00000004
					0x00000004
					0x00000004
					0x00000004
					0x00000004
					0x00000004
					0x00000004
					0x00000004
					0x00000004
					0x00000000
					0x00000000
					0x00000000
					0x00000000
					0x00000000
					0x00000000
					0x00000000
					0x00000000
					0x0000400d
					0x0000400d
					0x00000000
					0x00000011
					0x00000011
					0x00000000
					0x00000000
					0x00000000
					0x00000000
					0x00000000
					0x00000000
					0x00000000
					0x00000000
					0x00000000
					0x00000004
					0x00000004
					0x00000004
					0x00000004
					0x00000004
					0x00000004
					0x00000004
					0x00000004
					0x00000004
					0x00000004
					0x00000004
					0x00000004
					0x00000004
					0x00000004
					0x00000004
					0x00000004
					0x00000009
					0x00000009
					0x00000009
					0x00000009
					0x0000000a
					0x00000009
					0x0000000a
					0x00000009
					0x00000220
					0x00000000
					0x00100100
					0x00000000
					0x00000000
					0x77ffc004
					0x00000303
					0x81f1f008
					0x07070000
					0x00000000
					0x015ddddd
					0x5d75d720
					0x00514514
					0x00514514
					0x5d75d700
					0x0000003f
					0x00000000
					0x00000000
					0x0000014d
					0x039c0019
					0x00000000
					0x00000007
					0x00004080
					0x80001c77
					0x00000017
				>;
			};

		};
	};

	memory-controller@70019000 {
		emc-timings-3 {
			nvidia,ram-code = <3>;

			timing-12750000 {
				clock-frequency = <12750000>;

				nvidia,emem-configuration = <
					0x40040001
					0x8000000a
					0x00000001
					0x00000003
					0x00000004
					0x00000000
					0x00000003
					0x00000001
					0x00000002
					0x00000007
					0x00000002
					0x00000001
					0x00000004
					0x00000005
					0x05040102
					0x000b0604
					0x77230305
					0x70000f03
					0x001f0000
				>;
			};

			timing-20400000 {
				clock-frequency = <20400000>;

				nvidia,emem-configuration = <
					0x40020001
					0x80000012
					0x00000001
					0x00000003
					0x00000004
					0x00000000
					0x00000003
					0x00000001
					0x00000002
					0x00000007
					0x00000002
					0x00000001
					0x00000004
					0x00000005
					0x05040102
					0x000b0604
					0x74630305
					0x70000f03
					0x001f0000
				>;
			};

			timing-40800000 {
				clock-frequency = <40800000>;

				nvidia,emem-configuration = <
					0xa0000001
					0x80000017
					0x00000001
					0x00000003
					0x00000004
					0x00000000
					0x00000003
					0x00000001
					0x00000002
					0x00000007
					0x00000002
					0x00000001
					0x00000004
					0x00000005
					0x05040102
					0x000b0604
					0x73030305
					0x70000f03
					0x001f0000
				>;
			};

			timing-68000000 {
				clock-frequency = <68000000>;

				nvidia,emem-configuration = <
					0x00000001
					0x8000001e
					0x00000001
					0x00000003
					0x00000004
					0x00000000
					0x00000003
					0x00000001
					0x00000002
					0x00000007
					0x00000002
					0x00000001
					0x00000004
					0x00000005
					0x05040102
					0x000b0604
					0x72630405
					0x70000f03
					0x001f0000
				>;
			};

			timing-102000000 {
				clock-frequency = <102000000>;

				nvidia,emem-configuration = <
					0x08000001
					0x80000026
					0x00000001
					0x00000002
					0x00000005
					0x00000001
					0x00000003
					0x00000001
					0x00000002
					0x00000007
					0x00000002
					0x00000001
					0x00000004
					0x00000005
					0x05040102
					0x000b0605
					0x72430506
					0x70000f03
					0x001f0000
				>;
			};

			timing-204000000 {
				clock-frequency = <204000000>;

				nvidia,emem-configuration = <
					0x01000003
					0x80000040
					0x00000001
					0x00000002
					0x00000007
					0x00000003
					0x00000005
					0x00000001
					0x00000002
					0x00000007
					0x00000003
					0x00000001
					0x00000005
					0x00000005
					0x05050103
					0x000b0607
					0x71e40a08
					0x70000f03
					0x001f0000
				>;
			};

			timing-300000000 {
				clock-frequency = <300000000>;

				nvidia,emem-configuration = <
					0x08000004
					0x80000040
					0x00000001
					0x00000002
					0x00000009
					0x00000005
					0x00000007
					0x00000001
					0x00000002
					0x00000007
					0x00000003
					0x00000001
					0x00000005
					0x00000005
					0x05050103
					0x000c0709
					0x71c50e0a
					0x70000f03
					0x001f0000
				>;
			};

			timing-396000000 {
				clock-frequency = <396000000>;

				nvidia,emem-configuration = <
					0x0f000005
					0x80000040
					0x00000002
					0x00000003
					0x0000000c
					0x00000007
					0x00000009
					0x00000001
					0x00000002
					0x00000007
					0x00000003
					0x00000001
					0x00000005
					0x00000005
					0x05050103
					0x000e090c
					0x71c6120d
					0x70000f03
					0x001f0000
				>;
			};

			timing-528000000 {
				clock-frequency = <528000000>;

				nvidia,emem-configuration = <
					0x0f000007
					0x80000040
					0x00000003
					0x00000004
					0x00000010
					0x0000000a
					0x0000000d
					0x00000002
					0x00000002
					0x00000009
					0x00000003
					0x00000001
					0x00000006
					0x00000006
					0x06060103
					0x00120b10
					0x71c81811
					0x70000f03
					0x001f0000
				>;
			};

			timing-600000000 {
				clock-frequency = <600000000>;

				nvidia,emem-configuration = <
					0x00000009
					0x80000040
					0x00000004
					0x00000005
					0x00000012
					0x0000000b
					0x0000000e
					0x00000002
					0x00000003
					0x0000000a
					0x00000003
					0x00000001
					0x00000006
					0x00000007
					0x07060103
					0x00140d12
					0x71c91b13
					0x70000f03
					0x001f0000
				>;
			};

			timing-792000000 {
				clock-frequency = <792000000>;

				nvidia,emem-configuration = <
					0x0e00000b
					0x80000040
					0x00000006
					0x00000007
					0x00000018
					0x0000000f
					0x00000013
					0x00000003
					0x00000003
					0x0000000c
					0x00000003
					0x00000001
					0x00000008
					0x00000008
					0x08080103
					0x001a1118
					0x71ac2419
					0x70000f02
					0x001f0000
				>;
			};

			timing-924000000 {
				clock-frequency = <924000000>;

				nvidia,emem-configuration = <
					0x0e00000d
					0x80000040
					0x00000007
					0x00000008
					0x0000001b
					0x00000012
					0x00000017
					0x00000004
					0x00000004
					0x0000000e
					0x00000004
					0x00000001
					0x00000009
					0x00000009
					0x09090104
					0x001e141b
					0x71ae2a1c
					0x70000f02
					0x001f0000
				>;
			};

		};
	};
};
